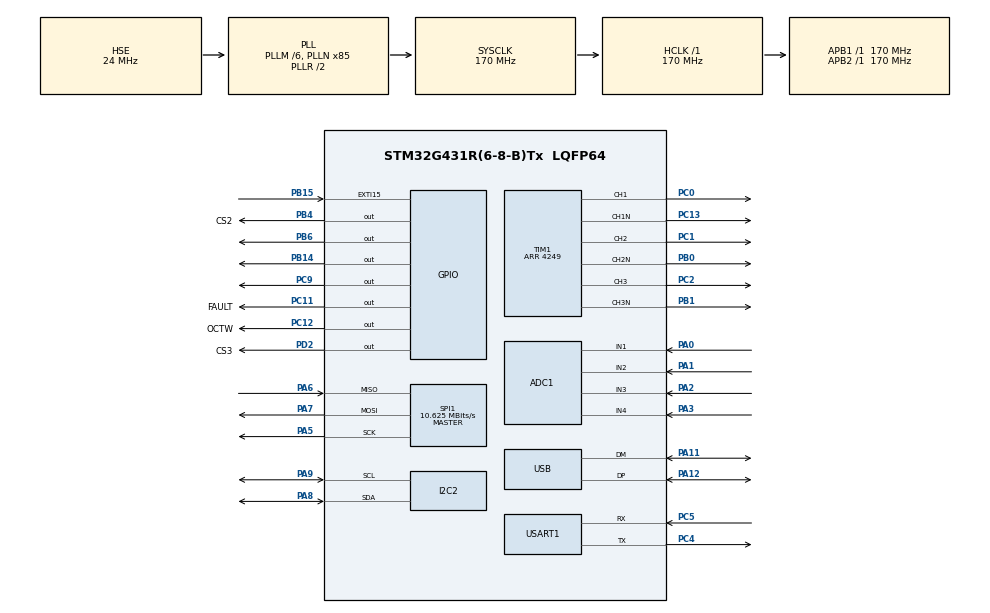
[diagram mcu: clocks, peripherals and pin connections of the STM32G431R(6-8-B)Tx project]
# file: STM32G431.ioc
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ADC1.Channel-0\#ChannelRegularConversion=ADC_CHANNEL_1
ADC1.Channel-1\#ChannelRegularConversion=ADC_CHANNEL_2
ADC1.Channel-2\#ChannelRegularConversion=ADC_CHANNEL_3
ADC1.Channel-3\#ChannelRegularConversion=ADC_CHANNEL_4
ADC1.ContinuousConvMode=DISABLE
ADC1.DMAContinuousRequests=ENABLE
ADC1.ExternalTrigConv=ADC_EXTERNALTRIG_T1_TRGO
ADC1.NbrOfConversion=4
ADC1.NbrOfConversionFlag=1
ADC1.OffsetNumber-0\#ChannelRegularConversion=ADC_OFFSET_NONE
ADC1.OffsetNumber-1\#ChannelRegularConversion=ADC_OFFSET_NONE
ADC1.OffsetNumber-2\#ChannelRegularConversion=ADC_OFFSET_NONE
ADC1.OffsetNumber-3\#ChannelRegularConversion=ADC_OFFSET_NONE
ADC1.Overrun=ADC_OVR_DATA_OVERWRITTEN
ADC1.Rank-0\#ChannelRegularConversion=1
ADC1.Rank-1\#ChannelRegularConversion=2
ADC1.Rank-2\#ChannelRegularConversion=3
ADC1.Rank-3\#ChannelRegularConversion=4
ADC1.SamplingTime-0\#ChannelRegularConversion=ADC_SAMPLETIME_2CYCLES_5
ADC1.SamplingTime-1\#ChannelRegularConversion=ADC_SAMPLETIME_2CYCLES_5
ADC1.SamplingTime-2\#ChannelRegularConversion=ADC_SAMPLETIME_2CYCLES_5
ADC1.SamplingTime-3\#ChannelRegularConversion=ADC_SAMPLETIME_2CYCLES_5
ADC1.master=1
Dma.ADC1.1.Direction=DMA_PERIPH_TO_MEMORY
Dma.ADC1.1.EventEnable=DISABLE
Dma.ADC1.1.Instance=DMA1_Channel2
Dma.ADC1.1.MemDataAlignment=DMA_MDATAALIGN_HALFWORD
Dma.ADC1.1.MemInc=DMA_MINC_ENABLE
Dma.ADC1.1.Mode=DMA_CIRCULAR
Dma.ADC1.1.PeriphDataAlignment=DMA_PDATAALIGN_HALFWORD
Dma.ADC1.1.PeriphInc=DMA_PINC_DISABLE
Dma.ADC1.1.Polarity=HAL_DMAMUX_REQ_GEN_RISING
Dma.ADC1.1.Priority=DMA_PRIORITY_LOW
Dma.ADC1.1.RequestNumber=1
Dma.ADC1.1.SignalID=NONE
Dma.ADC1.1.SyncEnable=DISABLE
Dma.ADC1.1.SyncPolarity=HAL_DMAMUX_SYNC_NO_EVENT
Dma.ADC1.1.SyncRequestNumber=1
Dma.ADC1.1.SyncSignalID=NONE
Dma.Request0=USART1_TX
Dma.Request1=ADC1
Dma.USART1_TX.0.Direction=DMA_MEMORY_TO_PERIPH
Dma.USART1_TX.0.EventEnable=DISABLE
Dma.USART1_TX.0.Instance=DMA1_Channel1
Dma.USART1_TX.0.MemDataAlignment=DMA_MDATAALIGN_BYTE
Dma.USART1_TX.0.MemInc=DMA_MINC_ENABLE
Dma.USART1_TX.0.Mode=DMA_CIRCULAR
Dma.USART1_TX.0.PeriphDataAlignment=DMA_PDATAALIGN_BYTE
Dma.USART1_TX.0.PeriphInc=DMA_PINC_DISABLE
Dma.USART1_TX.0.Polarity=HAL_DMAMUX_REQ_GEN_RISING
Dma.USART1_TX.0.Priority=DMA_PRIORITY_LOW
Dma.USART1_TX.0.RequestNumber=1
Dma.USART1_TX.0.SignalID=NONE
Dma.USART1_TX.0.SyncEnable=DISABLE
Dma.USART1_TX.0.SyncPolarity=HAL_DMAMUX_SYNC_NO_EVENT
Dma.USART1_TX.0.SyncRequestNumber=1
Dma.USART1_TX.0.SyncSignalID=NONE
I2C2.Timing=0x40B285C2
Mcu.Family=STM32G4
Mcu.Name=STM32G431R(6-8-B)Tx
Mcu.Package=LQFP64
NVIC.DMA1_Channel1_IRQn=true\:0\:0\:false\:false\:true\:false\:true\:true
NVIC.EXTI15_10_IRQn=true\:0\:0\:false\:false\:true\:true\:true\:true
NVIC.PriorityGroup=NVIC_PRIORITYGROUP_4
NVIC.USB_HP_IRQn=true\:0\:0\:false\:false\:true\:true\:true\:true
NVIC.USB_LP_IRQn=true\:0\:0\:false\:false\:true\:false\:true\:true
PA0.Mode=IN1-Single-Ended
PA0.Signal=ADC1_IN1
PA1.Mode=IN2-Single-Ended
PA1.Signal=ADC1_IN2
PA11.Mode=Device
PA11.Signal=USB_DM
PA12.Mode=Device
PA12.Signal=USB_DP
PA2.Mode=IN3-Single-Ended
PA2.Signal=ADC1_IN3
PA3.Mode=IN4-Single-Ended
PA3.Signal=ADC1_IN4
PA5.Mode=Full_Duplex_Master
PA5.Signal=SPI1_SCK
PA6.Mode=Full_Duplex_Master
PA6.Signal=SPI1_MISO
PA7.Mode=Full_Duplex_Master
PA7.Signal=SPI1_MOSI
PA8.Mode=I2C
PA8.Signal=I2C2_SDA
PA9.Mode=I2C
PA9.Signal=I2C2_SCL
PB0.GPIO_Speed=GPIO_SPEED_FREQ_VERY_HIGH
PB0.Mode=PWM Generation2 CH2 CH2N
PB0.Signal=TIM1_CH2N
PB1.GPIO_Speed=GPIO_SPEED_FREQ_VERY_HIGH
PB1.Mode=PWM Generation3 CH3 CH3N
PB1.Signal=TIM1_CH3N
PB14.GPIO_PuPd=GPIO_PULLDOWN
PB14.PinState=GPIO_PIN_RESET
PB14.Signal=GPIO_Output
PB15.GPIO_ModeDefaultEXTI=GPIO_MODE_IT_RISING
PB15.GPIO_PuPd=GPIO_PULLDOWN
PB15.Signal=GPXTI15
PB4.GPIO_Label=CS2
PB4.GPIO_PuPd=GPIO_PULLUP
PB4.PinState=GPIO_PIN_RESET
PB4.Signal=GPIO_Output
PB6.Signal=GPIO_Output
PC0.GPIO_PuPd=GPIO_NOPULL
PC0.GPIO_Speed=GPIO_SPEED_FREQ_VERY_HIGH
PC0.Signal=S_TIM1_CH1
PC1.GPIO_PuPd=GPIO_NOPULL
PC1.GPIO_Speed=GPIO_SPEED_FREQ_VERY_HIGH
PC1.Signal=S_TIM1_CH2
PC11.GPIO_Label=FAULT
PC11.GPIO_PuPd=GPIO_NOPULL
PC11.PinState=GPIO_PIN_RESET
PC11.Signal=GPIO_Output
PC12.GPIO_Label=OCTW
PC12.Signal=GPIO_Output
PC13.Mode=PWM Generation1 CH1 CH1N
PC13.Signal=TIM1_CH1N
PC2.GPIO_Speed=GPIO_SPEED_FREQ_VERY_HIGH
PC2.Signal=S_TIM1_CH3
PC4.Mode=Asynchronous
PC4.Signal=USART1_TX
PC5.Mode=Asynchronous
PC5.Signal=USART1_RX
PC9.GPIO_PuPd=GPIO_PULLUP
PC9.Signal=GPIO_Output
PD2.GPIO_Label=CS3
PD2.GPIO_PuPd=GPIO_PULLUP
PD2.PinState=GPIO_PIN_SET
PD2.Signal=GPIO_Output
PF0-OSC_IN.Mode=HSE-External-Oscillator
PF0-OSC_IN.Signal=RCC_OSC_IN
PF1-OSC_OUT.Mode=HSE-External-Oscillator
PF1-OSC_OUT.Signal=RCC_OSC_OUT
ProjectManager.HeapSize=0x200
ProjectManager.StackSize=0x400
ProjectManager.TargetToolchain=MDK-ARM V5
RCC.ADC12Freq_Value=170000000
RCC.AHBFreq_Value=170000000
RCC.APB1Freq_Value=170000000
RCC.APB1TimFreq_Value=170000000
RCC.APB2Freq_Value=170000000
RCC.APB2TimFreq_Value=170000000
RCC.CK48CLockSelection=RCC_USBCLKSOURCE_HSI48
RCC.CortexFreq_Value=170000000
RCC.EXTERNAL_CLOCK_VALUE=12288000
RCC.HCLKFreq_Value=170000000
RCC.HSE_VALUE=24000000
RCC.HSI48_VALUE=48000000
RCC.HSI_VALUE=16000000
RCC.LSE_VALUE=32768
RCC.PLLM=RCC_PLLM_DIV6
RCC.PLLN=85
RCC.PLLSourceVirtual=RCC_PLLSOURCE_HSE
RCC.SYSCLKFreq_VALUE=170000000
RCC.SYSCLKSource=RCC_SYSCLKSOURCE_PLLCLK
RCC.USBFreq_Value=48000000
RCC.VCOOutputFreq_Value=340000000
SH.S_TIM1_CH1.0=TIM1_CH1,PWM Generation1 CH1 CH1N
SH.S_TIM1_CH2.0=TIM1_CH2,PWM Generation2 CH2 CH2N
SH.S_TIM1_CH3.0=TIM1_CH3,PWM Generation3 CH3 CH3N
SPI1.BaudRatePrescaler=SPI_BAUDRATEPRESCALER_16
SPI1.CLKPhase=SPI_PHASE_2EDGE
SPI1.CLKPolarity=SPI_POLARITY_HIGH
SPI1.CalculateBaudRate=10.625 MBits/s
SPI1.DataSize=SPI_DATASIZE_8BIT
SPI1.Direction=SPI_DIRECTION_2LINES
SPI1.Mode=SPI_MODE_MASTER
SPI1.VirtualType=VM_MASTER
TIM1.AutomaticOutput=TIM_AUTOMATICOUTPUT_DISABLE
TIM1.Channel-PWM\ Generation1\ CH1\ CH1N=TIM_CHANNEL_1
TIM1.Channel-PWM\ Generation2\ CH2\ CH2N=TIM_CHANNEL_2
TIM1.Channel-PWM\ Generation3\ CH3\ CH3N=TIM_CHANNEL_3
TIM1.CounterMode=TIM_COUNTERMODE_CENTERALIGNED1
TIM1.OffStateIDLEMode=TIM_OSSI_DISABLE
TIM1.OffStateRunMode=TIM_OSSR_DISABLE
TIM1.PeriodNoDither=4249
TIM1.PulseNoDither_1=2125
TIM1.PulseNoDither_2=2125
TIM1.RepetitionCounter=0
TIM1.TIM_MasterOutputTrigger=TIM_TRGO_RESET
USART1.VirtualMode-Asynchronous=VM_ASYNC
USB.battery_charging_enable=DISABLE
USB.low_power_enable=DISABLE
USB.lpm_enable=DISABLE
USB_DEVICE.CLASS_NAME_FS=CDC
USB_DEVICE.VirtualMode=Cdc
USB_DEVICE.VirtualModeFS=Cdc_FS
VP_SYS_VS_DBSignals.Mode=DisableDeadBatterySignals
VP_TIM1_VS_ClockSourceINT.Mode=Internal
VP_USB_DEVICE_VS_USB_DEVICE_CDC_FS.Mode=CDC_FS
board=custom

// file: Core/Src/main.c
/* USER CODE BEGIN Header */
/**
  ******************************************************************************
  * @file           : main.c
  * @brief          : Main program body
  ******************************************************************************
  * @attention
  *
  * Copyright (c) 2026 STMicroelectronics.
  * All rights reserved.
  *
  * This software is licensed under terms that can be found in the LICENSE file
  * in the root directory of this software component.
  * If no LICENSE file comes with this software, it is provided AS-IS.
  *
  ******************************************************************************
  */
/* USER CODE END Header */
#include "main.h"
#include "adc.h"
#include "dma.h"
#include "i2c.h"
#include "spi.h"
#include "tim.h"
#include "usart.h"
#include "usb_device.h"
#include "gpio.h"

void SystemClock_Config(void);

int main(void)
{

  /* MCU Configuration--------------------------------------------------------*/

  /* Reset of all peripherals, Initializes the Flash interface and the Systick. */
  HAL_Init();

  /* Configure the system clock */
  SystemClock_Config();

  /* Initialize all configured peripherals */
  MX_GPIO_Init();
  MX_DMA_Init();
  MX_TIM1_Init();
  MX_USART1_UART_Init();
  MX_ADC1_Init();
  MX_I2C2_Init();
  MX_SPI1_Init();
  //MX_USB_Device_Init();
  /* USER CODE BEGIN 2 */

	// ===== 2. 启动 TIM1 六路互补 PWM =====
	HAL_GPIO_WritePin(GPIOB, GPIO_PIN_6, 1);  // 使能驱动（根据硬件设计）
	HAL_TIM_PWM_Start(&htim1, TIM_CHANNEL_1);
	HAL_TIM_PWM_Start(&htim1, TIM_CHANNEL_2);
	HAL_TIM_PWM_Start(&htim1, TIM_CHANNEL_3);
	HAL_TIMEx_PWMN_Start(&htim1, TIM_CHANNEL_1);
	HAL_TIMEx_PWMN_Start(&htim1, TIM_CHANNEL_2);
	HAL_TIMEx_PWMN_Start(&htim1, TIM_CHANNEL_3);

	// 初始输出 50% 占空比（中心对齐模式，中点 = ARR/2）
	TIM1->CCR1 = 2125;
	TIM1->CCR2 = 2125;
	TIM1->CCR3 = 2125;

  /* USER CODE END 2 */

  /* Infinite loop */
  while (1)
  {

  }
}

void SystemClock_Config(void)
{
  RCC_OscInitTypeDef RCC_OscInitStruct = {0};
  RCC_ClkInitTypeDef RCC_ClkInitStruct = {0};

  /** Configure the main internal regulator output voltage
  */
  HAL_PWREx_ControlVoltageScaling(PWR_REGULATOR_VOLTAGE_SCALE1_BOOST);

  /** Initializes the RCC Oscillators according to the specified parameters
  * in the RCC_OscInitTypeDef structure.
  */
  RCC_OscInitStruct.OscillatorType = RCC_OSCILLATORTYPE_HSI48|RCC_OSCILLATORTYPE_HSE;
  RCC_OscInitStruct.HSEState = RCC_HSE_ON;
  RCC_OscInitStruct.HSI48State = RCC_HSI48_ON;
  RCC_OscInitStruct.PLL.PLLState = RCC_PLL_ON;
  RCC_OscInitStruct.PLL.PLLSource = RCC_PLLSOURCE_HSE;
  RCC_OscInitStruct.PLL.PLLM = RCC_PLLM_DIV6;
  RCC_OscInitStruct.PLL.PLLN = 85;
  RCC_OscInitStruct.PLL.PLLP = RCC_PLLP_DIV2;
  RCC_OscInitStruct.PLL.PLLQ = RCC_PLLQ_DIV2;
  RCC_OscInitStruct.PLL.PLLR = RCC_PLLR_DIV2;
  if (HAL_RCC_OscConfig(&RCC_OscInitStruct) != HAL_OK)
  {
    Error_Handler();
  }

  /** Initializes the CPU, AHB and APB buses clocks
  */
  RCC_ClkInitStruct.ClockType = RCC_CLOCKTYPE_HCLK|RCC_CLOCKTYPE_SYSCLK
                              |RCC_CLOCKTYPE_PCLK1|RCC_CLOCKTYPE_PCLK2;
  RCC_ClkInitStruct.SYSCLKSource = RCC_SYSCLKSOURCE_PLLCLK;
  RCC_ClkInitStruct.AHBCLKDivider = RCC_SYSCLK_DIV1;
  RCC_ClkInitStruct.APB1CLKDivider = RCC_HCLK_DIV1;
  RCC_ClkInitStruct.APB2CLKDivider = RCC_HCLK_DIV1;

  if (HAL_RCC_ClockConfig(&RCC_ClkInitStruct, FLASH_LATENCY_4) != HAL_OK)
  {
    Error_Handler();
  }
}

void Error_Handler(void)
{
  __disable_irq();
  while (1)
  {
  }
}
